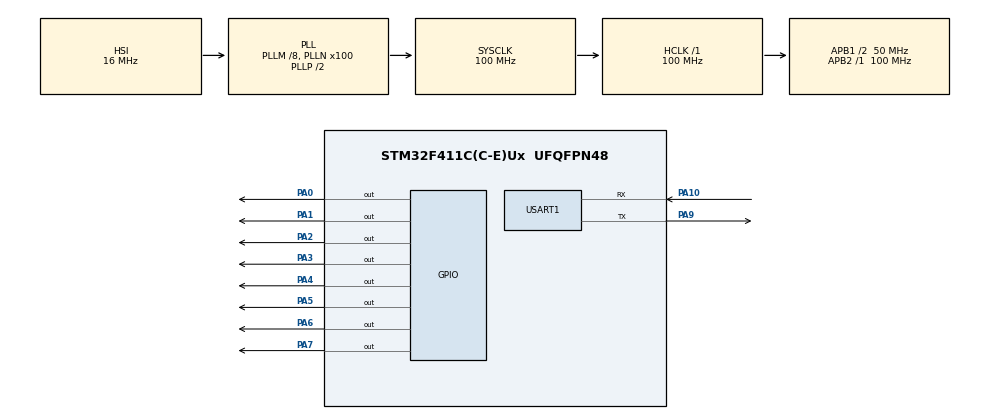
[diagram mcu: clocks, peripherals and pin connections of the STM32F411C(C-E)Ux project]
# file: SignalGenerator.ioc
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Dma.Request0=TIM1_UP
Dma.TIM1_UP.0.Direction=DMA_MEMORY_TO_PERIPH
Dma.TIM1_UP.0.FIFOMode=DMA_FIFOMODE_DISABLE
Dma.TIM1_UP.0.Instance=DMA2_Stream5
Dma.TIM1_UP.0.MemDataAlignment=DMA_MDATAALIGN_WORD
Dma.TIM1_UP.0.MemInc=DMA_MINC_ENABLE
Dma.TIM1_UP.0.Mode=DMA_NORMAL
Dma.TIM1_UP.0.PeriphDataAlignment=DMA_PDATAALIGN_WORD
Dma.TIM1_UP.0.PeriphInc=DMA_PINC_DISABLE
Dma.TIM1_UP.0.Priority=DMA_PRIORITY_LOW
Mcu.Family=STM32F4
Mcu.Name=STM32F411C(C-E)Ux
Mcu.Package=UFQFPN48
NVIC.DMA2_Stream5_IRQn=true\:0\:0\:false\:false\:true\:false\:true\:true
NVIC.PriorityGroup=NVIC_PRIORITYGROUP_4
NVIC.USART1_IRQn=true\:0\:0\:false\:false\:true\:true\:true\:true
PA0-WKUP.Signal=GPIO_Output
PA1.Signal=GPIO_Output
PA10.Mode=Asynchronous
PA10.Signal=USART1_RX
PA13.Mode=Serial_Wire
PA13.Signal=SYS_JTMS-SWDIO
PA14.Mode=Serial_Wire
PA14.Signal=SYS_JTCK-SWCLK
PA2.Signal=GPIO_Output
PA3.Signal=GPIO_Output
PA4.Signal=GPIO_Output
PA5.Signal=GPIO_Output
PA6.Signal=GPIO_Output
PA7.Signal=GPIO_Output
PA9.Mode=Asynchronous
PA9.Signal=USART1_TX
PC14-OSC32_IN.Mode=LSE-External-Oscillator
PC14-OSC32_IN.Signal=RCC_OSC32_IN
PC15-OSC32_OUT.Mode=LSE-External-Oscillator
PC15-OSC32_OUT.Signal=RCC_OSC32_OUT
PH0\ -\ OSC_IN.Mode=HSE-External-Oscillator
PH0\ -\ OSC_IN.Signal=RCC_OSC_IN
PH1\ -\ OSC_OUT.Mode=HSE-External-Oscillator
PH1\ -\ OSC_OUT.Signal=RCC_OSC_OUT
ProjectManager.HeapSize=0x200
ProjectManager.StackSize=0x400
ProjectManager.TargetToolchain=STM32CubeIDE
RCC.48MHZClocksFreq_Value=50000000
RCC.AHBFreq_Value=100000000
RCC.APB1CLKDivider=RCC_HCLK_DIV2
RCC.APB1Freq_Value=50000000
RCC.APB1TimFreq_Value=100000000
RCC.APB2Freq_Value=100000000
RCC.APB2TimFreq_Value=100000000
RCC.CortexFreq_Value=100000000
RCC.HCLKFreq_Value=100000000
RCC.HSE_VALUE=25000000
RCC.HSI_VALUE=16000000
RCC.PLLM=8
RCC.PLLN=100
RCC.SYSCLKFreq_VALUE=100000000
RCC.SYSCLKSource=RCC_SYSCLKSOURCE_PLLCLK
RCC.VCOOutputFreq_Value=200000000
TIM1.Period=2
TIM1.Prescaler=50000
USART1.VirtualMode=VM_ASYNC
VP_TIM1_VS_ClockSourceINT.Mode=Internal
board=custom

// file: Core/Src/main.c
/* USER CODE BEGIN Header */
/**
  ******************************************************************************
  * @file           : main.c
  * @brief          : Main program body
  ******************************************************************************
  * @attention
  *
  * Copyright (c) 2026 STMicroelectronics.
  * All rights reserved.
  *
  * This software is licensed under terms that can be found in the LICENSE file
  * in the root directory of this software component.
  * If no LICENSE file comes with this software, it is provided AS-IS.
  *
  ******************************************************************************
  */

/* USER CODE END Header */
#include "main.h"

/* USER CODE BEGIN Includes */
#include "RunTime.h"

/* USER CODE END Includes */

TIM_HandleTypeDef htim1;
DMA_HandleTypeDef hdma_tim1_up;

UART_HandleTypeDef huart1;

void SystemClock_Config(void);
static void MX_GPIO_Init(void);
static void MX_DMA_Init(void);
static void MX_TIM1_Init(void);
static void MX_USART1_UART_Init(void);
/* USER CODE BEGIN PFP */

/*
 * оголошуємо функцію користувача для обробки переривання
 */
//void DMA_TransferComplete(DMA_HandleTypeDef *hdma); // help GPT
/* USER CODE END PFP */

int main(void)
{

  /* MCU Configuration--------------------------------------------------------*/

  /* Reset of all peripherals, Initializes the Flash interface and the Systick. */
  HAL_Init();

  /* Configure the system clock */
  SystemClock_Config();

  /* Initialize all configured peripherals */
  MX_GPIO_Init();
  MX_DMA_Init();
  MX_TIM1_Init();
  MX_USART1_UART_Init();
  /* USER CODE BEGIN 2 */

  /*
   * 	Виявляється прис створенні переривання в DMA IQRHandler, HAL та CUbeMX не привязує функцію до самого переивання
   * 	тобто воно відбуваєтся але в нічого не робмть
   *
   * 	Данним рядком, ми до адреси ДМА що відповідає за переривання -> hdma_tim1_up.XferCpltCallback
   * 	привязуємо функцію яку буде використовувати користувач при викоику переривання
   */
  //hdma_tim1_up.XferCpltCallback = DMA_TransferComplete; // gpt help init interapt

  AppInit();

  /* USER CODE END 2 */

  /* Infinite loop */
  /* USER CODE BEGIN WHILE */
  while (1)
  {
	  AppRuntime();
    /* USER CODE END WHILE */

  }
}

void SystemClock_Config(void)
{
  RCC_OscInitTypeDef RCC_OscInitStruct = {0};
  RCC_ClkInitTypeDef RCC_ClkInitStruct = {0};

  /** Configure the main internal regulator output voltage
  */
  __HAL_RCC_PWR_CLK_ENABLE();
  __HAL_PWR_VOLTAGESCALING_CONFIG(PWR_REGULATOR_VOLTAGE_SCALE1);

  /** Initializes the RCC Oscillators according to the specified parameters
  * in the RCC_OscInitTypeDef structure.
  */
  RCC_OscInitStruct.OscillatorType = RCC_OSCILLATORTYPE_HSI;
  RCC_OscInitStruct.HSIState = RCC_HSI_ON;
  RCC_OscInitStruct.HSICalibrationValue = RCC_HSICALIBRATION_DEFAULT;
  RCC_OscInitStruct.PLL.PLLState = RCC_PLL_ON;
  RCC_OscInitStruct.PLL.PLLSource = RCC_PLLSOURCE_HSI;
  RCC_OscInitStruct.PLL.PLLM = 8;
  RCC_OscInitStruct.PLL.PLLN = 100;
  RCC_OscInitStruct.PLL.PLLP = RCC_PLLP_DIV2;
  RCC_OscInitStruct.PLL.PLLQ = 4;
  if (HAL_RCC_OscConfig(&RCC_OscInitStruct) != HAL_OK)
  {
    Error_Handler();
  }

  /** Initializes the CPU, AHB and APB buses clocks
  */
  RCC_ClkInitStruct.ClockType = RCC_CLOCKTYPE_HCLK|RCC_CLOCKTYPE_SYSCLK
                              |RCC_CLOCKTYPE_PCLK1|RCC_CLOCKTYPE_PCLK2;
  RCC_ClkInitStruct.SYSCLKSource = RCC_SYSCLKSOURCE_PLLCLK;
  RCC_ClkInitStruct.AHBCLKDivider = RCC_SYSCLK_DIV1;
  RCC_ClkInitStruct.APB1CLKDivider = RCC_HCLK_DIV2;
  RCC_ClkInitStruct.APB2CLKDivider = RCC_HCLK_DIV1;

  if (HAL_RCC_ClockConfig(&RCC_ClkInitStruct, FLASH_LATENCY_3) != HAL_OK)
  {
    Error_Handler();
  }
}

static void MX_TIM1_Init(void)
{

  TIM_ClockConfigTypeDef sClockSourceConfig = {0};
  TIM_MasterConfigTypeDef sMasterConfig = {0};

  htim1.Instance = TIM1;
  htim1.Init.Prescaler = 50000;
  htim1.Init.CounterMode = TIM_COUNTERMODE_UP;
  htim1.Init.Period = 2000;
  htim1.Init.ClockDivision = TIM_CLOCKDIVISION_DIV1;
  htim1.Init.RepetitionCounter = 0;
  htim1.Init.AutoReloadPreload = TIM_AUTORELOAD_PRELOAD_DISABLE;
  if (HAL_TIM_Base_Init(&htim1) != HAL_OK)
  {
    Error_Handler();
  }
  sClockSourceConfig.ClockSource = TIM_CLOCKSOURCE_INTERNAL;
  if (HAL_TIM_ConfigClockSource(&htim1, &sClockSourceConfig) != HAL_OK)
  {
    Error_Handler();
  }
  sMasterConfig.MasterOutputTrigger = TIM_TRGO_RESET;
  sMasterConfig.MasterSlaveMode = TIM_MASTERSLAVEMODE_DISABLE;
  if (HAL_TIMEx_MasterConfigSynchronization(&htim1, &sMasterConfig) != HAL_OK)
  {
    Error_Handler();
  }

}

static void MX_USART1_UART_Init(void)
{

  huart1.Instance = USART1;
  huart1.Init.BaudRate = 115200;
  huart1.Init.WordLength = UART_WORDLENGTH_8B;
  huart1.Init.StopBits = UART_STOPBITS_1;
  huart1.Init.Parity = UART_PARITY_NONE;
  huart1.Init.Mode = UART_MODE_TX_RX;
  huart1.Init.HwFlowCtl = UART_HWCONTROL_NONE;
  huart1.Init.OverSampling = UART_OVERSAMPLING_16;
  if (HAL_UART_Init(&huart1) != HAL_OK)
  {
    Error_Handler();
  }

}

static void MX_DMA_Init(void)
{

  /* DMA controller clock enable */
  __HAL_RCC_DMA2_CLK_ENABLE();

  /* DMA interrupt init */
  /* DMA2_Stream5_IRQn interrupt configuration */
  HAL_NVIC_SetPriority(DMA2_Stream5_IRQn, 0, 0);
  HAL_NVIC_EnableIRQ(DMA2_Stream5_IRQn);

}

static void MX_GPIO_Init(void)
{
  GPIO_InitTypeDef GPIO_InitStruct = {0};

  /* GPIO Ports Clock Enable */
  __HAL_RCC_GPIOC_CLK_ENABLE();
  __HAL_RCC_GPIOH_CLK_ENABLE();
  __HAL_RCC_GPIOA_CLK_ENABLE();

  /*Configure GPIO pin Output Level */
  HAL_GPIO_WritePin(GPIOA, GPIO_PIN_0|GPIO_PIN_1|GPIO_PIN_2|GPIO_PIN_3
                          |GPIO_PIN_4|GPIO_PIN_5|GPIO_PIN_6|GPIO_PIN_7, GPIO_PIN_RESET);

  /*Configure GPIO pins : PA0 PA1 PA2 PA3
                           PA4 PA5 PA6 PA7 */
  GPIO_InitStruct.Pin = GPIO_PIN_0|GPIO_PIN_1|GPIO_PIN_2|GPIO_PIN_3
                          |GPIO_PIN_4|GPIO_PIN_5|GPIO_PIN_6|GPIO_PIN_7;
  GPIO_InitStruct.Mode = GPIO_MODE_OUTPUT_PP;
  GPIO_InitStruct.Pull = GPIO_NOPULL;
  GPIO_InitStruct.Speed = GPIO_SPEED_FREQ_LOW;
  HAL_GPIO_Init(GPIOA, &GPIO_InitStruct);

  /* USER CODE BEGIN MX_GPIO_Init_2 */
  //GPIO_InitStruct.Speed = GPIO_SPEED_FREQ_VERY_HIGH;
  /* USER CODE END MX_GPIO_Init_2 */
}

void Error_Handler(void)
{
  __disable_irq();
  while (1)
  {
  }
}
